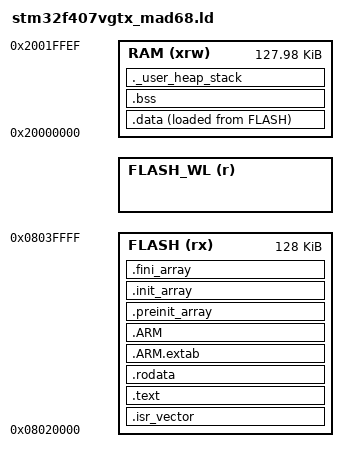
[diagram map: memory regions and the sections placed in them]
/*
******************************************************************************
**
** @file        : LinkerScript.ld
**
** @author      : Auto-generated by STM32CubeIDE
**
** @brief       : Linker script for STM32F446RETx Device from STM32F4 series
**                      512Kbytes FLASH
**                      128Kbytes RAM
**
**                Set heap size, stack size and stack location according
**                to application requirements.
**
**                Set memory bank area and size if external memory is used
**
**  Target      : STMicroelectronics STM32
**
**  Distribution: The file is distributed as is, without any warranty
**                of any kind.
**
******************************************************************************
** @attention
**
** <h2><center>&copy; Copyright (c) 2021 STMicroelectronics.
** All rights reserved.</center></h2>
**
** This software component is licensed by ST under BSD 3-Clause license,
** the "License"; You may not use this file except in compliance with the
** License. You may obtain a copy of the License at:
**                        opensource.org/licenses/BSD-3-Clause
**
******************************************************************************
*/

/* Entry Point */
ENTRY(Reset_Handler)

/* Highest address of the user mode stack */
_estack = ORIGIN(RAM) + LENGTH(RAM); /* end of "RAM" Ram type memory */
/* MAD68 HE: the vendor IAP bootloader checks 0x96969696 at 0x2001FFFC.
 * The top 16 bytes of SRAM are kept out of the stack/heap so the flag and the
 * fail-safe bookkeeping survive a jump into the bootloader. */
_board_bootloader_flag = 0x2001FFFC;
_board_failsafe_state = 0x2001FFF0;

_Min_Heap_Size = 0x200; /* required amount of heap */
_Min_Stack_Size = 0x400; /* required amount of stack */

/* Memories definition */
/* Application lives in flash sector 5 only (0x08020000-0x0803FFFF), which is
 * exactly the region the vendor bootloader programs. Sectors 0-4 (vendor
 * bootloader + stock settings) and 6 are never touched; sector 7 holds this
 * firmware's wear-leveled settings. */
BASE_ADDR = 0x8000000;
APP_ADDR = 0x8020000;
APP_SIZE = 128K;
MEMORY
{
  FLASH    (rx)   : ORIGIN = APP_ADDR, LENGTH = APP_SIZE
  FLASH_WL (r)    : ORIGIN = BASE_ADDR + WL_BASE_ADDRESS, LENGTH = FLASH_SIZE - WL_BASE_ADDRESS
  RAM    (xrw)    : ORIGIN = 0x20000000, LENGTH = 128K - 16 /* top 16 bytes: bootloader flag + fail-safe state */
}

/* Sections */
SECTIONS
{
  /* The startup code into "FLASH" Rom type memory */
  .isr_vector :
  {
    . = ALIGN(4);
    KEEP(*(.isr_vector)) /* Startup code */
    . = ALIGN(4);
  } >FLASH

  /* The program code and other data into "FLASH" Rom type memory */
  .text :
  {
    . = ALIGN(4);
    *(.text)           /* .text sections (code) */
    *(.text*)          /* .text* sections (code) */
    *(.glue_7)         /* glue arm to thumb code */
    *(.glue_7t)        /* glue thumb to arm code */
    *(.eh_frame)

    KEEP (*(.init))
    KEEP (*(.fini))

    . = ALIGN(4);
    _etext = .;        /* define a global symbols at end of code */
  } >FLASH

  /* Constant data into "FLASH" Rom type memory */
  .rodata :
  {
    . = ALIGN(4);
    *(.rodata)         /* .rodata sections (constants, strings, etc.) */
    *(.rodata*)        /* .rodata* sections (constants, strings, etc.) */
    . = ALIGN(4);
  } >FLASH

  .ARM.extab   : {
    . = ALIGN(4);
    *(.ARM.extab* .gnu.linkonce.armextab.*)
    . = ALIGN(4);
  } >FLASH

  .ARM : {
    . = ALIGN(4);
    __exidx_start = .;
    *(.ARM.exidx*)
    __exidx_end = .;
    . = ALIGN(4);
  } >FLASH

  .preinit_array     :
  {
    . = ALIGN(4);
    PROVIDE_HIDDEN (__preinit_array_start = .);
    KEEP (*(.preinit_array*))
    PROVIDE_HIDDEN (__preinit_array_end = .);
    . = ALIGN(4);
  } >FLASH

  .init_array :
  {
    . = ALIGN(4);
    PROVIDE_HIDDEN (__init_array_start = .);
    KEEP (*(SORT(.init_array.*)))
    KEEP (*(.init_array*))
    PROVIDE_HIDDEN (__init_array_end = .);
    . = ALIGN(4);
  } >FLASH

  .fini_array :
  {
    . = ALIGN(4);
    PROVIDE_HIDDEN (__fini_array_start = .);
    KEEP (*(SORT(.fini_array.*)))
    KEEP (*(.fini_array*))
    PROVIDE_HIDDEN (__fini_array_end = .);
    . = ALIGN(4);
  } >FLASH

  /* Used by the startup to initialize data */
  _sidata = LOADADDR(.data);

  /* Initialized data sections into "RAM" Ram type memory */
  .data :
  {
    . = ALIGN(4);
    _sdata = .;        /* create a global symbol at data start */
    *(.data)           /* .data sections */
    *(.data*)          /* .data* sections */
    *(.RamFunc)        /* .RamFunc sections */
    *(.RamFunc*)       /* .RamFunc* sections */

    . = ALIGN(4);
    _edata = .;        /* define a global symbol at data end */

  } >RAM AT> FLASH

  /* Uninitialized data section into "RAM" Ram type memory */
  . = ALIGN(4);
  .bss :
  {
    /* This is used by the startup in order to initialize the .bss section */
    _sbss = .;         /* define a global symbol at bss start */
    __bss_start__ = _sbss;
    *(.bss)
    *(.bss*)
    *(COMMON)

    . = ALIGN(4);
    _ebss = .;         /* define a global symbol at bss end */
    __bss_end__ = _ebss;
  } >RAM

  /* User_heap_stack section, used to check that there is enough "RAM" Ram  type memory left */
  ._user_heap_stack :
  {
    . = ALIGN(8);
    PROVIDE ( end = . );
    PROVIDE ( _end = . );
    . = . + _Min_Heap_Size;
    . = . + _Min_Stack_Size;
    . = ALIGN(8);
  } >RAM

  /* Remove information from the compiler libraries */
  /DISCARD/ :
  {
    libc.a ( * )
    libm.a ( * )
    libgcc.a ( * )
  }

  .ARM.attributes 0 : { *(.ARM.attributes) }
}

/* Hard guarantees checked at link time. */
ASSERT(ORIGIN(FLASH) == 0x08020000, "app must start at sector 5")
ASSERT(ORIGIN(FLASH) + LENGTH(FLASH) <= 0x08040000, "app must not spill past sector 5")
ASSERT(ORIGIN(FLASH_WL) >= 0x08060000, "settings must live in sector 7")
